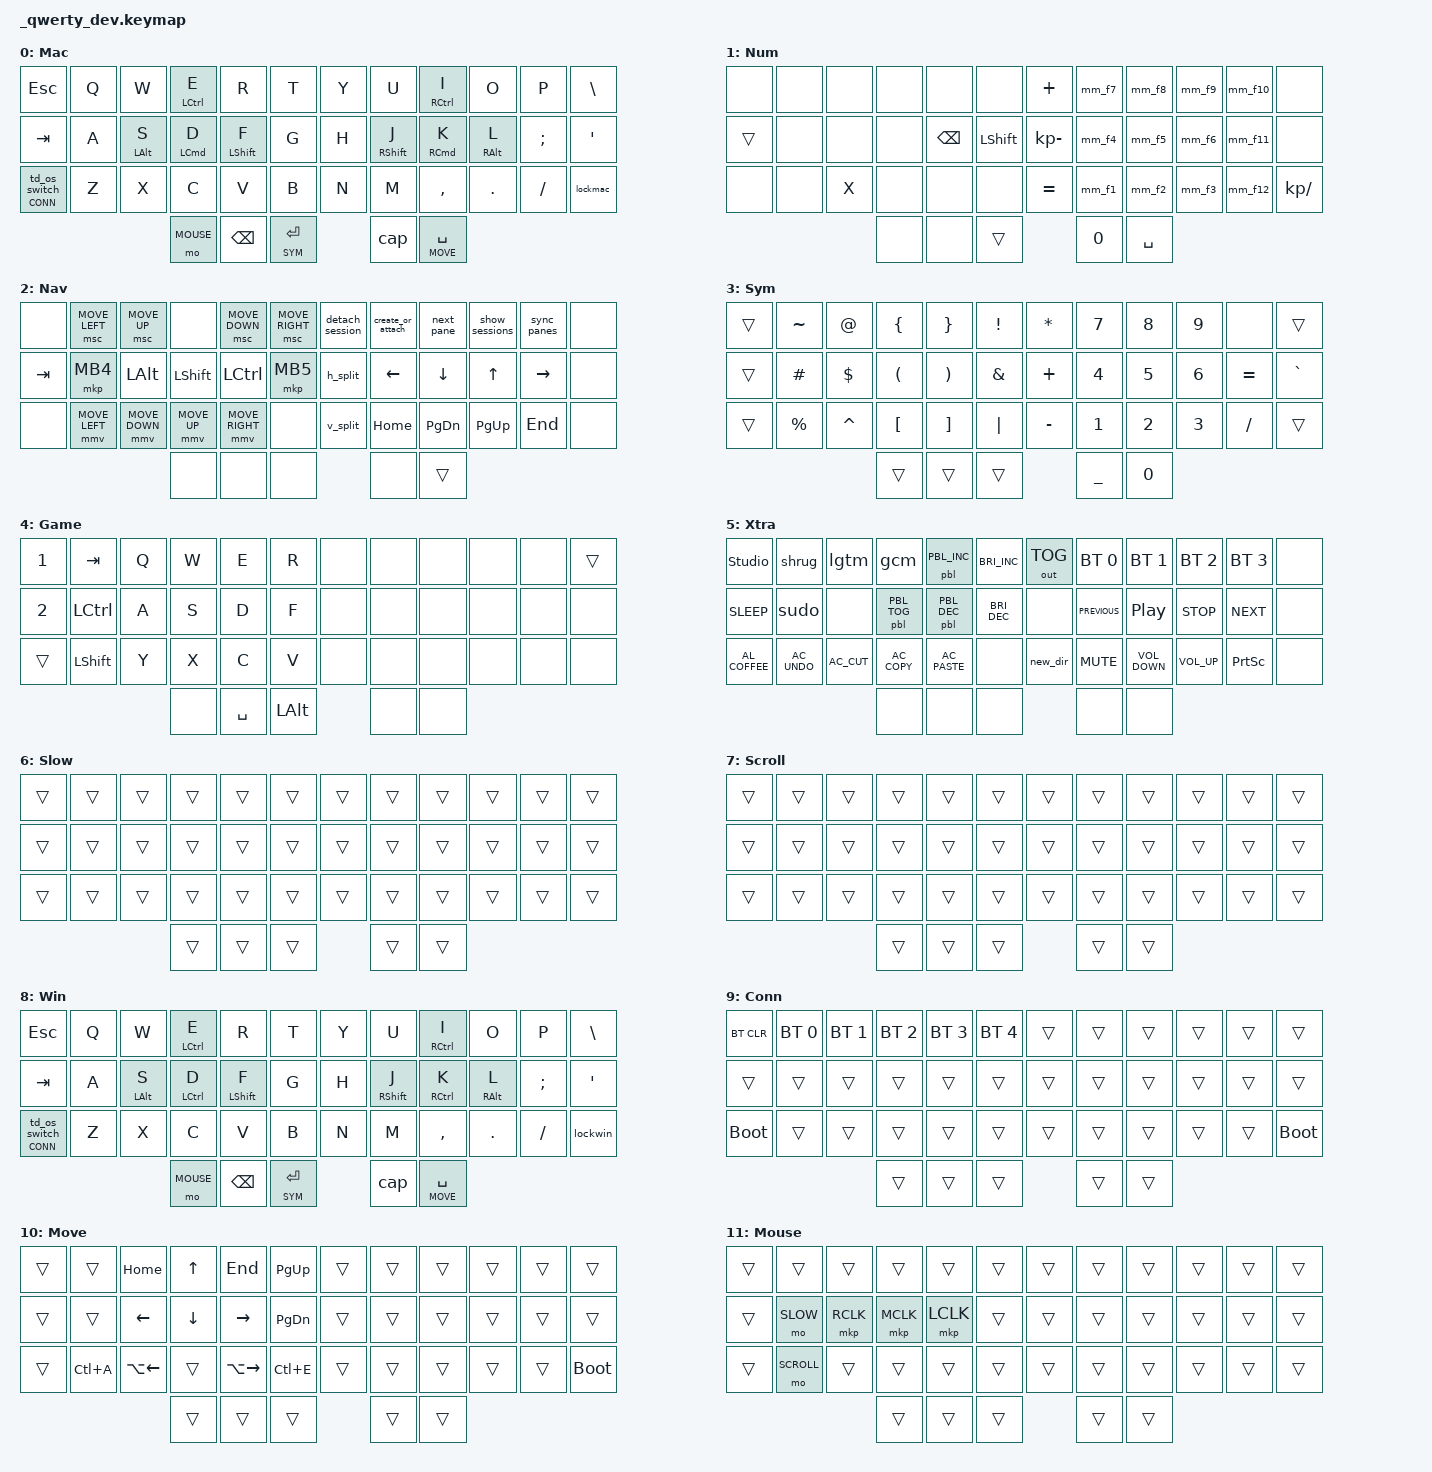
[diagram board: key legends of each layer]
/* upstream bindings and behaviors */
#include <behaviors.dtsi>
#include <dt-bindings/zmk/bt.h>
#include <dt-bindings/zmk/keys.h>
#include <dt-bindings/zmk/mouse.h>
#include <dt-bindings/zmk/outputs.h>
#include <behaviors/mouse_keys.dtsi>
#include <dt-bindings/zmk/ext_power.h>

/* local overlays */
#include "keymap_features/prospector_brightness.dtsi"
#include "keymap_features/macros.dtsi"
#include "keymap_features/behaviors.dtsi"
#include "keymap_features/combos.dtsi"

/ {
/* --- KEYMAP CONFIG --- */
// ╭──────┬──────┬──────┬──────┬──────┬──────╮  ╭──────┬──────┬──────┬──────┬──────┬──────╮
//    00     01     02     03    04      05        06     07     08     09     10     11
// ├──────┼──────┼──────┼──────┼──────┼──────┤  ├──────┼──────┼──────┼──────┼──────┼──────┤
//    12     13     14     15    16      17        18     19     20     21     22     23
// ├──────┼──────┼──────┼──────┼──────┼──────┤  ├──────┼──────┼──────┼──────┼──────┼──────┤
//    24     25     26     27    28      29        30     31     32     33     34     35
// ╰──────┴──────┴──────┼──────┼──────┼──────┤  ├──────┼──────┼──────┴──────┴──────┴──────╯
//                         36     37     38        39     40
//                      ╰──────┴──────┴──────╯  ╰──────┴──────╯
#define MAC     0
#define NUM     1
#define NAV     2
#define SYM     3
#define GAME    4
#define EXTRAS  5
#define SLOW    6
#define SCROLL  7
#define WIN     8   // ported from corne-wireless-view-zmk: Windows-style base layer
#define CONN    9   // ported from corne-wireless-view-zmk: BT connection layer
#define MOVE    10  // ported from corne-wireless-view-zmk: move_layer
#define MOUSE   11  // S/D/F = right/middle/left click

// This shared keymap builds for prospector and non-prospector firmwares.
// This stubs the key bindings that are contained in the prospector module
// so non-prospector firmware can build.
#ifndef CONFIG_SHIELD_PROSPECTOR_ADAPTER
    behaviors {
        /omit-if-no-ref/ pbl: prospector_brightness_stub {
            compatible = "zmk,behavior-macro-two-param";
            #binding-cells = <2>;
            bindings = <&none>;
        };
    };
#endif

// Ported from corne-wireless-view-zmk-config: right thumb now combines
// hold-for-connection-layer with tap-dance OS/layout switching that used
// to live on two separate keys (left thumb `&mo LCON`, right thumb `&lay`).
    behaviors {
        td_os_switch: td_os_switch {
            compatible = "zmk,behavior-tap-dance";
            #binding-cells = <0>;
            tapping-term-ms = <280>;
            bindings = <&kp LEFT_GUI>, <&to MAC>, <&to WIN>, <&to GAME>; // tap(GUI), double(MAC), triple(WIN), quad(GAME)
        };

        conn_or_os: conn_or_os_switch {
            compatible = "zmk,behavior-hold-tap";
            #binding-cells = <2>;
            flavor = "hold-preferred";
            tapping-term-ms = <200>;
            bindings = <&mo>, <&td_os_switch>; // hold = layer, tap = td_os_switch (2nd param unused, pass 0)
        };

        // Ported verbatim from corne-wireless-view-zmk-config's lockmac/lockwin.
        lockmac: tap_dance_lockmac {
            compatible = "zmk,behavior-tap-dance";
            #binding-cells = <0>;
            tapping-term-ms = <200>;
            bindings = <&none>, <&kp LC(LG(Q))>; // tap, double-tap
        };

        lockwin: tap_dance_lockwin {
            compatible = "zmk,behavior-tap-dance";
            #binding-cells = <0>;
            tapping-term-ms = <200>;
            bindings = <&none>, <&kp LG(L)>; // tap, double-tap
        };

        // Ported verbatim from corne-wireless-view-zmk-config's tap_dance_cap.
        cap: tap_dance_cap {
            compatible = "zmk,behavior-tap-dance";
            #binding-cells = <0>;
            tapping-term-ms = <160>;
            bindings = <&kp DEL>, <&caps_word>; // tap, double-tap
        };
    };

    keymap {
        compatible = "zmk,keymap";
        MAC {
            display-name = "Mac";
            bindings = <
    &kp ESC          &kp Q            &kp W            &ht_left LCTRL E  &kp R             &kp T     &kp Y   &kp U              &ht_right RCTRL I  &kp O             &kp P           &kp BSLH
    &kp TAB          &kp A            &ht_left LALT S  &ht_left LCMD D   &ht_left LSHFT F  &kp G     &kp H   &ht_right RSHFT J  &ht_right RCMD K   &ht_right RALT L  &kp SEMICOLON   &kp SQT
    &conn_or_os CONN 0  &kp Z            &kp X            &kp C             &kp V             &kp B     &kp N   &kp M              &kp COMMA          &kp DOT           &kp FSLH        &lockmac
                                                       &mo MOUSE            &kp BACKSPACE     &lt SYM RET &cap  &lt MOVE SPACE
            >;
        };

        NUM { 
            display-name = "Num";
            bindings = <
&none   &none  &none   &none  &none          &none            &kp PLUS     &mm_f7             &mm_f8             &mm_f9             &mm_f10            &none
&trans   &none  &none  &none  &kp BACKSPACE  &kp LSHIFT       &kp KP_MINUS &mm_f4             &mm_f5             &mm_f6             &mm_f11            &none
&none    &none  &kp X  &none  &none          &none            &kp EQUAL    &mm_f1             &mm_f2             &mm_f3             &mm_f12            &kp KP_SLASH
                       &none  &none          &trans           &kp N0     &kp SPACE
            >;
        };

        NAV {
            display-name = "Nav";
            bindings = <
&none    &msc MOVE_LEFT  &msc MOVE_UP    &none        &msc MOVE_DOWN  &msc MOVE_RIGHT     &detach_session  &create_or_attach  &next_pane   &show_sessions  &sync_panes       &none
&kp TAB  &mkp MB4        &kp LALT        &kp LSHFT    &kp LCTRL       &mkp MB5            &h_split         &kp LEFT_ARROW     &kp DOWN     &kp UP          &kp RIGHT_ARROW   &none
&none    &mmv MOVE_LEFT  &mmv MOVE_DOWN  &mmv MOVE_UP &mmv MOVE_RIGHT &none               &v_split         &kp HOME           &kp PG_DN    &kp PG_UP       &kp END           &none
                                                      &none   &none   &none               &none   &trans
            >;
        };

        SYM {
            display-name = "Sym";
            bindings = <
&trans  &kp TILDE  &kp AT      &kp LEFT_BRACE        &kp RIGHT_BRACE        &kp EXCLAMATION  &kp STAR   &kp N7  &kp N8  &kp N9  &none      &trans
&trans  &kp POUND  &kp DOLLAR  &kp LEFT_PARENTHESIS  &kp RIGHT_PARENTHESIS  &kp AMPERSAND    &kp PLUS   &kp N4  &kp N5  &kp N6  &kp EQUAL  &kp GRAVE
&trans  &kp PERCENT &kp CARET  &kp LEFT_BRACKET      &kp RIGHT_BRACKET      &kp PIPE         &kp MINUS  &kp N1  &kp N2  &kp N3  &kp SLASH  &trans
                                       &trans  &trans     &trans            &kp UNDERSCORE   &kp N0
            >;
        };

        GAME {
            display-name = "Game";
            bindings = <
&kp N1  &kp TAB    &kp Q  &kp W   &kp E      &kp R           &none  &none  &none  &none  &none  &trans
&kp N2  &kp LCTRL  &kp A  &kp S   &kp D      &kp F           &none  &none  &none  &none  &none  &none
&trans  &kp LSHFT  &kp Y  &kp X   &kp C      &kp V           &none  &none  &none  &none  &none  &none
                          &none   &kp SPACE  &kp LEFT_ALT    &none  &none
            >;
        };

        EXTRAS {
            display-name = "Xtra";
            bindings = <
&studio_unlock    &shrug          &lgtm           &gcm            &pbl PBL_INC    &kp C_BRIGHTNESS_INC    &out OUT_TOG  &bt BT_SEL 0    &bt BT_SEL 1       &bt BT_SEL 2      &bt BT_SEL 3     &none
&kp C_SLEEP       &sudo           &none           &pbl PBL_TOG    &pbl PBL_DEC    &kp C_BRIGHTNESS_DEC    &none         &kp C_PREVIOUS  &kp C_PLAY_PAUSE   &kp C_STOP        &kp C_NEXT       &none
&kp C_AL_COFFEE   &kp C_AC_UNDO   &kp C_AC_CUT    &kp C_AC_COPY   &kp C_AC_PASTE  &none                   &new_dir      &kp K_MUTE      &kp C_VOLUME_DOWN  &kp C_VOLUME_UP   &kp PRINTSCREEN  &none
                                                                                   &none  &none  &none    &none         &none
            >;
        };

        SLOW {
            display-name = "Slow";
            bindings = <
// ╭────────┬────────┬────────┬────────┬────────┬────────╮  ╭────────┬────────┬────────┬────────┬────────┬────────╮
    &trans    &trans   &trans   &trans   &trans   &trans      &trans   &trans   &trans   &trans   &trans   &trans
// ├────────┼────────┼────────┼────────┼────────┼────────┤  ├────────┼────────┼────────┼────────┼────────┼────────┤
    &trans    &trans   &trans   &trans   &trans   &trans      &trans   &trans   &trans   &trans   &trans   &trans
// ├────────┼────────┼────────┼────────┼────────┼────────┤  ├────────┼────────┼────────┼────────┼────────┼────────┤
    &trans    &trans   &trans   &trans   &trans   &trans      &trans   &trans   &trans   &trans   &trans   &trans
// ╰────────┴────────┴────────┼────────┼────────┼────────┤  ├────────┼────────┼────────┴────────┴────────┴────────╯
                                  &trans   &trans   &trans      &trans   &trans
                             // ╰────────┴────────┴────────╯  ╰────────┴────────╯
            >;
        };

        SCROLL {
            display-name = "Scroll";
            bindings = <
// ╭────────┬────────┬────────┬────────┬────────┬────────╮  ╭────────┬────────┬────────┬────────┬────────┬────────╮
    &trans    &trans   &trans   &trans   &trans   &trans      &trans   &trans   &trans   &trans   &trans   &trans
// ├────────┼────────┼────────┼────────┼────────┼────────┤  ├────────┼────────┼────────┼────────┼────────┼────────┤
    &trans    &trans   &trans   &trans   &trans   &trans      &trans   &trans   &trans   &trans   &trans   &trans
// ├────────┼────────┼────────┼────────┼────────┼────────┤  ├────────┼────────┼────────┼────────┼────────┼────────┤
    &trans    &trans   &trans   &trans   &trans   &trans      &trans   &trans   &trans   &trans   &trans   &trans
// ╰────────┴────────┴────────┼────────┼────────┼────────┤  ├────────┼────────┼────────┴────────┴────────┴────────╯
                                  &trans   &trans   &trans      &trans   &trans
                             // ╰────────┴────────┴────────╯  ╰────────┴────────╯
            >;
        };

        // Windows-style base layer, ported from corne-wireless-view-zmk-config.
        // Identical to BASE except LCMD/RCMD (Mac "super" modifier) become
        // LCTRL/RCTRL, matching corne's mac_layer/win_layer split.
        WIN {
            display-name = "Win";
            bindings = <
    &kp ESC          &kp Q            &kp W            &ht_left LCTRL E  &kp R             &kp T    &kp Y   &kp U              &ht_right RCTRL I  &kp O             &kp P           &kp BSLH
    &kp TAB          &kp A               &ht_left LALT S  &ht_left LCTRL D  &ht_left LSHFT F  &kp G    &kp H   &ht_right RSHFT J  &ht_right RCTRL K  &ht_right RALT L      &kp SEMICOLON                 &kp SQT
    &conn_or_os CONN 0  &kp Z            &kp X            &kp C             &kp V             &kp B    &kp N   &kp M              &kp COMMA          &kp DOT           &kp FSLH           &lockwin
                          &mo MOUSE   &kp BACKSPACE  &lt SYM RET   &cap  &lt MOVE SPACE
            >;
        };

        // BT connection layer, ported from corne-wireless-view-zmk-config's connect_layer.
        CONN {
            display-name = "Conn";
            bindings = <
    &bt BT_CLR  &bt BT_SEL 0  &bt BT_SEL 1  &bt BT_SEL 2  &bt BT_SEL 3  &bt BT_SEL 4  &trans   &trans      &trans     &trans   &trans      &trans
    &trans      &trans        &trans        &trans        &trans        &trans        &trans   &trans      &trans     &trans   &trans      &trans
    &bootloader &trans        &trans        &trans        &trans        &trans        &trans   &trans      &trans     &trans   &trans      &bootloader
                                        &trans        &trans        &trans        &trans   &trans
            >;
        };

        // Ported from corne-wireless-view-zmk-config's move_layer.
        MOVE {
            display-name = "Move";
            bindings = <
    &trans  &trans     &kp HOME      &kp UP    &kp END        &kp PG_UP   &trans   &trans      &trans     &trans   &trans      &trans
    &trans  &trans     &kp LEFT      &kp DOWN  &kp RIGHT      &kp PG_DN   &trans   &trans      &trans     &trans   &trans      &trans
    &trans  &kp LC(A)  &kp LA(LEFT)  &trans    &kp LA(RIGHT)  &kp LC(E)   &trans   &trans      &trans     &trans   &trans      &bootloader
                                        &trans   &trans      &trans   &trans      &trans
            >;
        };

        // S/D/F = right/middle/left click. A held = SLOW (precision pointer),
        // Z held = SCROLL (trackball becomes scroll wheel). Everything else passes through.
        MOUSE {
            display-name = "Mouse";
            bindings = <
    &trans  &trans  &trans     &trans     &trans     &trans   &trans  &trans  &trans  &trans  &trans  &trans
    &trans  &mo SLOW   &mkp RCLK  &mkp MCLK  &mkp LCLK  &trans   &trans  &trans  &trans  &trans  &trans  &trans
    &trans  &mo SCROLL   &trans     &trans     &trans     &trans   &trans  &trans  &trans  &trans  &trans  &trans
                                  &trans  &trans  &trans      &trans  &trans
            >;
        };
    };
};
